# ESP32S31_RADIO register map
Vendor: Espressif; Series: ESP32-S31; File version: 3.52
Registers are 32-bit, read-write, no defined reset value unless marked. A register's access mark holds for its fields unless they carry their own. Offsets are from the block's base; [hi:lo] are bit positions; {n}, {i} and the like mark numbered series.

## WIFI_MAC_RX_FILTER — Four WDEVRX_ABORT receive-queue policy words. Complete dbg_read_rx_misc names every used bit through 19; queue three is also the complete promiscuous-sniffer control word.
Base 0x201040D8
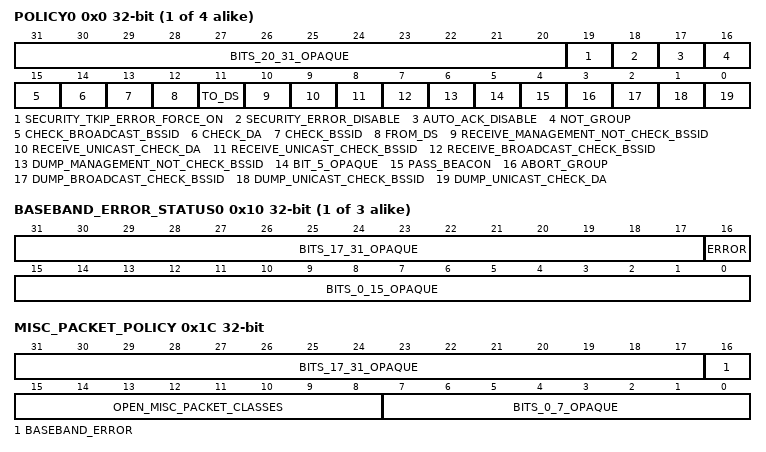
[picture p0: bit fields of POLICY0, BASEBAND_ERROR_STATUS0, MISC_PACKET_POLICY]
{0x0+4i} POLICY{i} (i=0..3) — Project-assigned name. WDEVRX_ABORT[0-3], updated through separate fresh-read RMW edges.
  [31:20] BITS_20_31_OPAQUE — Opaque: meaning not established.
  [19] SECURITY_TKIP_ERROR_FORCE_ON — Project-assigned name.
  [18] SECURITY_ERROR_DISABLE — Project-assigned name.
  [17] AUTO_ACK_DISABLE — Project-assigned name. Complete hal_sniffer_enable sets this bit first on queue three; the debug decoder names it AUTOACK_DISABLE.
  [16] NOT_GROUP — Project-assigned name.
  [15] CHECK_BROADCAST_BSSID — Project-assigned name.
  [14] CHECK_DA — Project-assigned name.
  [13] CHECK_BSSID — Project-assigned name.
  [12] FROM_DS — Project-assigned name.
  [11] TO_DS — Project-assigned name.
  [10] RECEIVE_MANAGEMENT_NOT_CHECK_BSSID — Project-assigned name.
  [9] RECEIVE_UNICAST_CHECK_DA — Project-assigned name.
  [8] RECEIVE_UNICAST_CHECK_BSSID — Project-assigned name. The policy-six UBSSID branch sets this bit before live vendor Authentication.
  [7] RECEIVE_BROADCAST_CHECK_BSSID — Project-assigned name.
  [6] DUMP_MANAGEMENT_NOT_CHECK_BSSID — Project-assigned name.
  [5] BIT_5_OPAQUE — Opaque: meaning not established.
  [4] PASS_BEACON — Project-assigned name.
  [3] ABORT_GROUP — Project-assigned name.
  [2] DUMP_BROADCAST_CHECK_BSSID — Project-assigned name.
  [1] DUMP_UNICAST_CHECK_BSSID — Project-assigned name. The policy-six UBSSID branch sets this bit before live vendor Authentication.
  [0] DUMP_UNICAST_CHECK_DA — Project-assigned name.
{0x10+4i} BASEBAND_ERROR_STATUS{i} (i=0..2) ro — Project-assigned name. First three words sampled by the bounded four-entry hal_ifc_get_bb_err_bitmap loop. Bit 16 contributes the corresponding output bitmap bit.
  [31:17] BITS_17_31_OPAQUE — Opaque: meaning not established. Observed source use; the individual hardware meaning is unknown.
  [16] ERROR — Project-assigned name.
  [15:0] BITS_0_15_OPAQUE — Opaque: meaning not established. Observed source use; the individual hardware meaning is unknown.
0x1C MISC_PACKET_POLICY — Project-assigned name. The open promiscuous RX frontier sets bits 15:8 together after the complete sniffer-enable leaf. The complete vendor misc-packet leaf independently proves this register and related packet-class fields. Complete hal_ifc_get_bb_err_bitmap reads bit 16 as the fourth baseband-error status bit.
  [31:17] BITS_17_31_OPAQUE — Opaque: meaning not established. Observed source use; the individual hardware meaning is unknown.
  [16] BASEBAND_ERROR ro — Project-assigned name. Fourth status bit sampled by the bounded hal_ifc_get_bb_err_bitmap loop.
  [15:8] OPEN_MISC_PACKET_CLASSES — Project-assigned name. Eight independent class-enable bits used by the working open scan/STA receive path; every eight-bit mask is representable.
  [7:0] BITS_0_7_OPAQUE — Opaque: meaning not established. Observed source use; the individual hardware meaning is unknown.

## WIFI_MAC_CONTROL — Shared MAC run/stop control. The cold open-RX frontier publishes zero; the complete vendor channel-switch chain requests quiescence here and later restarts the no-power-save profile.
Base 0x20104CAC
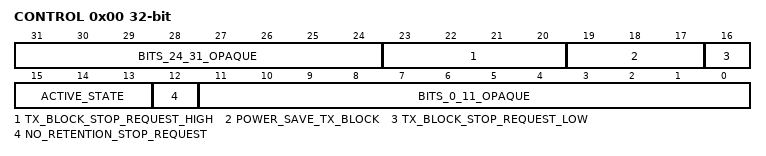
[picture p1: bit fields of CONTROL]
0x00 CONTROL — Project-assigned name. Cold promiscuous initialization writes zero. libpp[hal_mac.o]::hal_mac_deinit records bits 13 and 14 as TX/RX activity and sets bit 12 plus bits 23:16; hal_mac_init with WIFI_PS_NONE clears that same stop-request mask.
  [31:24] BITS_24_31_OPAQUE — Opaque: meaning not established.
  [23:20] TX_BLOCK_STOP_REQUEST_HIGH — Project-assigned name. Bits 23:20 of the eight stop-request bits libpp[hal_mac.o]::hal_mac_deinit sets and hal_mac_init clears with the WIFI_PS_NONE retention mask.
  [19:17] POWER_SAVE_TX_BLOCK — Project-assigned name. Bits 19:17 of the stop-request bits. The vendor power manager sets all three to block the TX queues when its coexistence slice ends and clears them to unblock; its retention mask keeps them out of the MAC deinit and init requests while an associated station runs power management.
    0=RUN (The TX queues run.); 7=BLOCKED (The TX queues are blocked.)
  [16] TX_BLOCK_STOP_REQUEST_LOW — Project-assigned name. Bit 16 of the eight stop-request bits libpp[hal_mac.o]::hal_mac_deinit sets and hal_mac_init clears with the WIFI_PS_NONE retention mask.
  [15:13] ACTIVE_STATE ro — Project-assigned name. Three-bit activity state polled until zero before PHY retuning. libpp[hal_mac.o]::hal_mac_deinit independently records bit 13 as TX active and bit 14 as RX active; bit 15 remains unnamed.
  [12] NO_RETENTION_STOP_REQUEST — Project-assigned name. Included in the MAC stop request and cleared by hal_mac_init for the WIFI_PS_NONE all-ones retention mask.
  [11:0] BITS_0_11_OPAQUE — Opaque: meaning not established.
